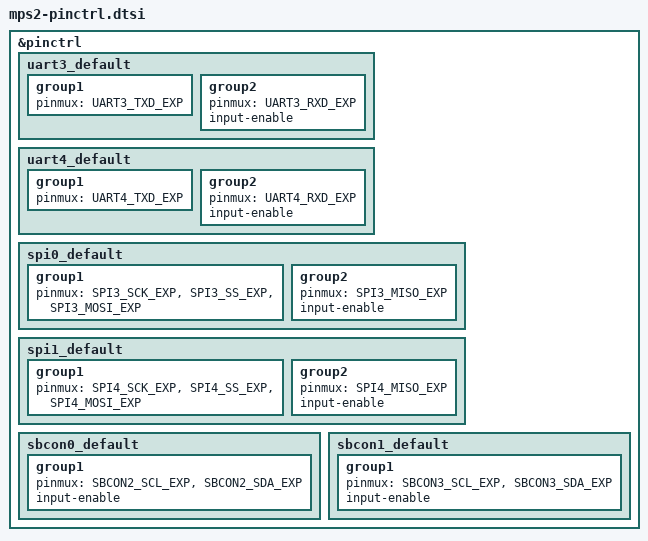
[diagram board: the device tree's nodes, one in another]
/*
 * Copyright 2025 Arm Limited and/or its affiliates <open-source-office@arm.com>
 *
 * SPDX-License-Identifier: Apache-2.0
 */

#include <zephyr/dt-bindings/pinctrl/arm-mps2-pinctrl.h>

&pinctrl {
	/omit-if-no-ref/  uart3_default: uart3_default {
		group1 {
			pinmux = <UART3_TXD_EXP>;
		};

		group2 {
			pinmux = <UART3_RXD_EXP>;
			input-enable;
		};
	};

	 /omit-if-no-ref/ uart4_default: uart4_default {
		 group1 {
			 pinmux = <UART4_TXD_EXP>;
		};

		group2 {
			pinmux = <UART4_RXD_EXP>;
			input-enable;
		};
	};

	/omit-if-no-ref/ spi0_default: spi0_default {
		group1 {
			pinmux = <SPI3_SCK_EXP>, <SPI3_SS_EXP>,
				  <SPI3_MOSI_EXP>;
		};
		group2 {
			pinmux = <SPI3_MISO_EXP>;
			input-enable;
		};
	};

	/omit-if-no-ref/ spi1_default: spi1_default {
		group1 {
			pinmux = <SPI4_SCK_EXP>, <SPI4_SS_EXP>,
				 <SPI4_MOSI_EXP>;
		};
		group2 {
			pinmux = <SPI4_MISO_EXP>;
			input-enable;
		};
	};

	/omit-if-no-ref/ sbcon0_default: sbcon0_default {
		group1 {
			pinmux = <SBCON2_SCL_EXP>, <SBCON2_SDA_EXP>;
			input-enable;
		};
	};

	/omit-if-no-ref/ sbcon1_default: sbcon1_default {
		group1 {
			pinmux = <SBCON3_SCL_EXP>, <SBCON3_SDA_EXP>;
			input-enable;
		};
	};
};
